# STM32L562 register map
File version: 1.0
CPU: CM33 r0p1, little endian, MPU, FPU, 3 interrupt priority bits
Registers are 32-bit, read-write, reset 0x0 unless marked. A register's access mark holds for its fields unless they carry their own. Offsets are from the block's base; [hi:lo] are bit positions; lines under a group give offsets from that group; {n}, {i} and the like mark numbered series; 'fields as' and 'values as' point back to an identical list.

## DBGMCU — MCU debug component
Base 0xE0044000
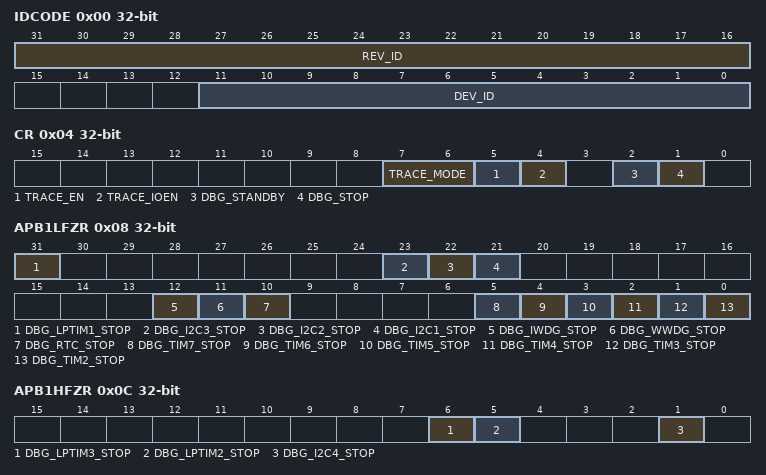
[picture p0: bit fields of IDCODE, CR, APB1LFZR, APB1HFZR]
0x00 IDCODE ro — DBGMCU_IDCODE
  [31:16] REV_ID — Revision identifie
  [11:0] DEV_ID — Device identifier
0x04 CR — Debug MCU configuration register
  [7:6] TRACE_MODE — Trace pin assignment control
  [5] TRACE_EN — trace port and clock enable
  [4] TRACE_IOEN — Trace pin assignment control
  [2] DBG_STANDBY — Debug Standby mode
  [1] DBG_STOP — Debug Stop mode
0x08 APB1LFZR — Debug MCU APB1 freeze register1
  [31] DBG_LPTIM1_STOP — LPTIM1 counter stopped when core is halted
  [23] DBG_I2C3_STOP — I2C3 SMBUS timeout counter stopped when core is halted
  [22] DBG_I2C2_STOP — I2C2 SMBUS timeout counter stopped when core is halted
  [21] DBG_I2C1_STOP — I2C1 SMBUS timeout counter stopped when core is halted
  [12] DBG_IWDG_STOP — Independent watchdog counter stopped when core is halted
  [11] DBG_WWDG_STOP — Window watchdog counter stopped when core is halted
  [10] DBG_RTC_STOP — RTC counter stopped when core is halted
  [5] DBG_TIM7_STOP — TIM7 counter stopped when core is halted
  [4] DBG_TIM6_STOP — TIM6 counter stopped when core is halted
  [3] DBG_TIM5_STOP — TIM5 stop in debug
  [2] DBG_TIM4_STOP — TIM4 stop in debug
  [1] DBG_TIM3_STOP — TIM3 stop in debug
  [0] DBG_TIM2_STOP — TIM2 counter stopped when core is halted
0x0C APB1HFZR — Debug MCU APB1 freeze register 2
  [6] DBG_LPTIM3_STOP — LPTIM3 stop in debug
  [5] DBG_LPTIM2_STOP — LPTIM2 counter stopped when core is halted
  [1] DBG_I2C4_STOP — I2C4 stop in debug
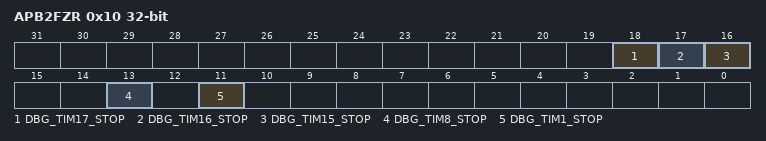
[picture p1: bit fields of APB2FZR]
0x10 APB2FZR — Debug MCU APB2 freeze register
  [18] DBG_TIM17_STOP
  [17] DBG_TIM16_STOP — TIM16 counter stopped when core is halted
  [16] DBG_TIM15_STOP — TIM15 counter stopped when core is halted
  [13] DBG_TIM8_STOP — TIM8 stop in debug
  [11] DBG_TIM1_STOP — TIM1 counter stopped when core is halted

## DCB — Debug Control Block
Base 0xE000EE08
0x00 DSCSR — Debug Security Control and Status Register
  [16] CDS — Current domain Secure

## DMA1 — Direct memory access controller
Base 0x40020000
Same registers: DMA2 0x40020400, SEC_DMA1 0x50020000, SEC_DMA2 0x50020400
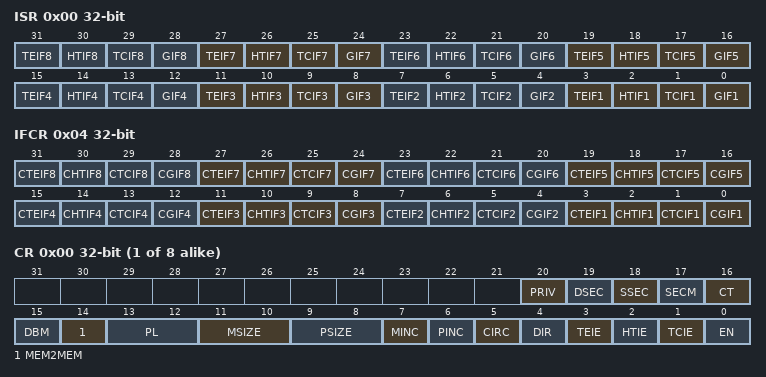
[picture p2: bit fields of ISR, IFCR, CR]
0x00 ISR ro — interrupt status register
  [4n-1] TEIF{n} (n=1..8) — Channel {n} Transfer Error flag
    0=NoError (No transfer error); 1=Error (A transfer error has occured)
  [4n-2] HTIF{n} (n=1..8) — Channel {n} Half Transfer Complete flag
    0=NotHalf (No half transfer event); 1=Half (A half transfer event has occured)
  [4n-3] TCIF{n} (n=1..8) — Channel {n} Transfer Complete flag
    0=NotComplete (No transfer complete event); 1=Complete (A transfer complete event has occured)
  [4n-4] GIF{n} (n=1..8) — Channel {n} Global interrupt flag
    0=NoEvent (No transfer error, half event, complete event); 1=Event (A transfer error, half event or complete event has occured)
0x04 IFCR wo — interrupt flag clear register
  [4n-1] CTEIF{n} (n=1..8) — Channel {n} Transfer Error clear
    1=Clears the TEIF flag in the ISR register
  [4n-2] CHTIF{n} (n=1..8) — Channel {n} Half Transfer clear
    1=Clears the HTIF flag in the ISR register
  [4n-3] CTCIF{n} (n=1..8) — Channel {n} Transfer Complete clear
    1=Clears the TCIF flag in the ISR register
  [4n-4] CGIF{n} (n=1..8) — Channel {n} Global interrupt clear
    1=Clears the GIF, TEIF, HTIF, TCIF flags in the ISR register
0x08 CH{i} (i=1..8; step 0x14) group — Channel cluster: CCR?, CNDTR?, CPAR?, CM0AR?, and CM1AR? registers
  0x00 CR — channel x configuration register
    [20] PRIV — privileged mode
    [19] DSEC — security of the DMA transfer to the destination
    [18] SSEC — security of the DMA transfer from the source
    [17] SECM — secure mode
    [16] CT — current target memory of DMA transfer in double-buffer mode
    [15] DBM — double-buffer mode
    [14] MEM2MEM — Memory to memory mode
      0=Disabled (Memory to memory mode disabled); 1=Enabled (Memory to memory mode enabled)
    [13:12] PL — Channel priority level
      0=Low (Low priority); 1=Medium priority; 2=High priority; 3=Very high priority
    [11:10] MSIZE — Memory size
      0=Bits8 (8-bit size); 1=Bits16 (16-bit size); 2=Bits32 (32-bit size)
    [9:8] PSIZE — Peripheral size
      values as MSIZE
    [7] MINC — Memory increment mode
      0=Disabled (Increment mode disabled); 1=Enabled (Increment mode enabled)
    [6] PINC — Peripheral increment mode
      values as MINC
    [5] CIRC — Circular mode
      0=Disabled (Circular buffer disabled); 1=Enabled (Circular buffer enabled)
    [4] DIR — Data transfer direction
      0=FromPeripheral (Read from peripheral); 1=FromMemory (Read from memory)
    [3] TEIE — Transfer error interrupt enable
      0=Disabled (Transfer Error interrupt disabled); 1=Enabled (Transfer Error interrupt enabled)
    [2] HTIE — Half transfer interrupt enable
      0=Disabled (Half Transfer interrupt disabled); 1=Enabled (Half Transfer interrupt enabled)
    [1] TCIE — Transfer complete interrupt enable
      0=Disabled (Transfer Complete interrupt disabled); 1=Enabled (Transfer Complete interrupt enabled)
    [0] EN — Channel enable
      0=Disabled (Channel disabled); 1=Enabled (Channel enabled)
  0x04 NDTR — channel x number of data register
    [17:0] NDT range 0..65535 — Number of data to transfer
  0x08 PAR — channel x peripheral address register
    [31:0] PA — Peripheral address
  0x0C M0AR — channel x memory address register
    [31:0] MA — Memory address
  0x10 M1AR — channel x memory address register
    [31:0] MA — peripheral address
